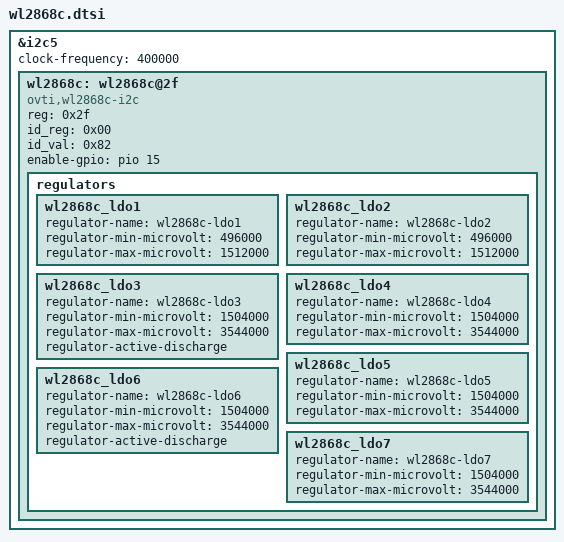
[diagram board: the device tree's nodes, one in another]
// SPDX-License-Identifier: GPL-2.0
//
// Copyright (c) 2021 MediaTek Inc.
&i2c5 {
	#address-cells = <1>;
	#size-cells = <0>;
	clock-frequency = <400000>;
	wl2868c: wl2868c@2f {
		status = "ok";
		compatible = "ovti,wl2868c-i2c";
		reg = <0x2f>;
		id_reg = <0x00>;
		id_val = <0x82>;
		enable-gpio = <&pio 15 0x0>;
		regulators {
			wl2868c_ldo1: wl2868c_ldo1 {
				regulator-name = "wl2868c-ldo1";
				regulator-min-microvolt = <496000>;
				regulator-max-microvolt = <1512000>;

			};
			wl2868c_ldo2: wl2868c_ldo2 {
				regulator-name = "wl2868c-ldo2";
				regulator-min-microvolt = <496000>;
				regulator-max-microvolt = <1512000>;

			};
			wl2868c_ldo3: wl2868c_ldo3 {
				regulator-name = "wl2868c-ldo3";
				regulator-min-microvolt = <1504000>;
				regulator-max-microvolt = <3544000>;
				regulator-active-discharge;
			};
			wl2868c_ldo4: wl2868c_ldo4 {
				regulator-name = "wl2868c-ldo4";
				regulator-min-microvolt = <1504000>;
				regulator-max-microvolt = <3544000>;
			};
			wl2868c_ldo5: wl2868c_ldo5 {
				regulator-name = "wl2868c-ldo5";
				regulator-min-microvolt = <1504000>;
				regulator-max-microvolt = <3544000>;
			};
			wl2868c_ldo6: wl2868c_ldo6 {
				regulator-name = "wl2868c-ldo6";
				regulator-min-microvolt = <1504000>;
				regulator-max-microvolt = <3544000>;
				regulator-active-discharge;
			};
			wl2868c_ldo7: wl2868c_ldo7 {
				regulator-name = "wl2868c-ldo7";
				regulator-min-microvolt = <1504000>;
				regulator-max-microvolt = <3544000>;
			};
		};
	};
};

